# aasrc_AASRC_CFG_02D00000h register map
Vendor: Texas Instruments
Peripheral module from a debugger description file (folder AM275x).
Registers are 32-bit, access per field, reset 0x0 unless marked. A register's access mark holds for its fields unless they carry their own. Offsets are as the file gives them; lines under a group give offsets from that group; [hi:lo] are bit positions; {n}, {i} and the like mark numbered series; 'fields as' and 'values as' point back to an identical list; <NAME> marks a mode.

## aasrc_cfg (part 1 of 2)
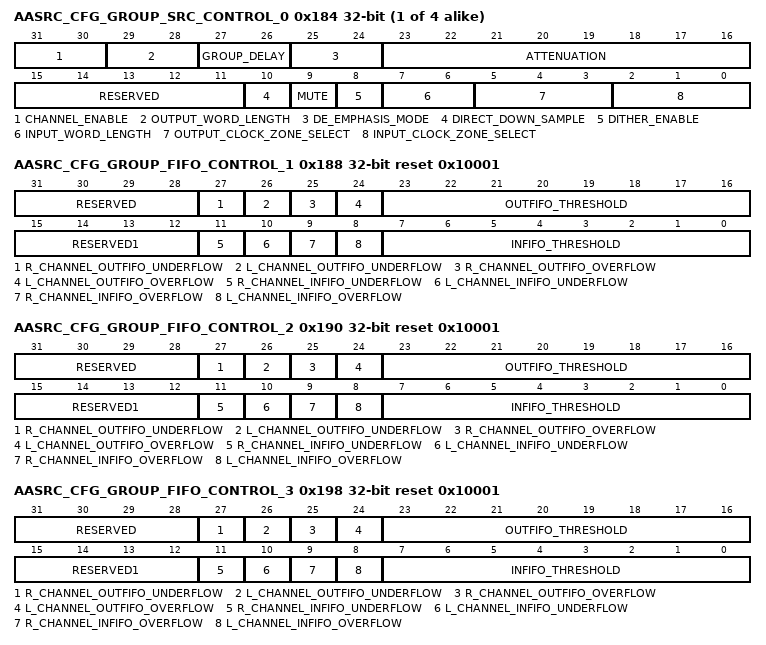
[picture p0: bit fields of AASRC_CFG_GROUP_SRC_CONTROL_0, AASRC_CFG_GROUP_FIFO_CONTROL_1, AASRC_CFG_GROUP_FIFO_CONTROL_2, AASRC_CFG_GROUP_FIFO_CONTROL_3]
{0x184+8i} AASRC_CFG_GROUP_SRC_CONTROL_{i} (i=0..3) — This is where all the SRCs of Group{i} is configured
  [31:30] CHANNEL_ENABLE rw — Setting this enables the Channels of Group{i} SRCs The output FIFOs for the stream must be enabled before the input FIFOs 00: No channel enabled 01: Only Right Channel enabled 10: Only Left Channel enabled 11: Both channels enabled Clearing this register will clear the data path
  [29:28] OUTPUT_WORD_LENGTH rw — These bits select the word length for the Group{i} SRC output data The word length reduction is performed by utilizing triangular PDF dithering 0: 24 Bits [Default] 1: 20 Bits 2: 18 Bits 3: 16 Bits
  [27:26] GROUP_DELAY rw — These bits select the interpolation filter group delay by configuring the number of samples which are pre-buffered prior to the re-sampler function 0: 64 Samples [Default] 1: 32 Samples 2: 16 Samples 3: 8 Samples
  [25:24] DE_EMPHASIS_MODE rw — These bits are utilized to enable or disable the digital de-emphasis filter manually The de-emphasis filter is intended to process 50/15s pre-emphasized audio material at the following input sampling rates 0: De-Emphasis Disabled [Default] 1: De-Emphasis Enabled for fS = 48kHz 2: De-Emphasis Enabled for fS = 441kHz 3: De-Emphasis Enabled for fS = 32kHz
  [23:16] ATTENUATION rw — These bits are utilized to configure the Group{i} SRC digital output attenuation for the stream Output Attenuation [dB] = N 05, where N = Attenuation[7:0]DEC
  [15:11] RESERVED ro — Always read as 0
  [10] DIRECT_DOWN_SAMPLE rw — This bit selects the mode of the decimation function, either true decimation filter or direct down-sampling without filtering DDN Decimation Function. Note: Direct down-sampling should only be used when the output sampling rate is higher than the input sampling rate When the output sampling rate is equal to or lower than the input sampling rate, the Decimation Filter must be used in order to avoid aliasing 0 Decimation Filter1 Direct Down Sampling
  [9] MUTE rw — This bit enables or disables the Group{i} SRC output soft mute function; output data set to all zeros 0 Mute disabled1 Mute enabled
  [8] DITHER_ENABLE rw — This bit enables or disables the Group{i} SRC filters dithering 0 Dithering disabled1 Dithering enabled
  [7:6] INPUT_WORD_LENGTH rw — These bits select the word length for the SRC0 input data 0: 24 Bits [Default] 1: 20 Bits 2: 18 Bits 3: 16 Bits
  [5:3] OUTPUT_CLOCK_ZONE_SELECT rw — This selects the output clock zone for the Group{i} SRCs It can select between the 4 external audio clock zones Based on this number rate and stamp is passed to the Stream0 Sample rate converter from respective clock recovery loop 00: This selects the Clock Recovery loop 0 01: This selects the Clock Recovery loop 1 10: This selects the Clock Recovery loop 2 11: This selects the Clock Recovery loop 3 In case of Galileo other values are not valid
  [2:0] INPUT_CLOCK_ZONE_SELECT rw — This selects the input clock zone for the Group{i} SRCs It can select between the 4 external audio clock zones Based on this number rate and stamp is passed to the Stream0 Sample rate converter from respective clock recovery loop 000: This selects the Clock Recovery loop 0 001: This selects the Clock Recovery loop 1 010: This selects the Clock Recovery loop 2 011: This selects the Clock Recovery loop 3 In case of Galileo other values are not valid
0x188 AASRC_CFG_GROUP_FIFO_CONTROL_1 reset 0x10001 — This register configures the FIFO settings for Group 1.
  [31:28] RESERVED ro — Always read as 0
  [27] R_CHANNEL_OUTFIFO_UNDERFLOW ro — This signal is set to 1 when any of the Right Channel OUTFIFO for Group1 SRCs is underflowed 0 No underflow is detected1 Underflow is detected
  [26] L_CHANNEL_OUTFIFO_UNDERFLOW ro — This signal is set to 1 when any of the Left Channel OUTFIFO for Group1 SRCs is underflowed 0 No underflow is detected1 Underflow is detected
  [25] R_CHANNEL_OUTFIFO_OVERFLOW ro — This signal is set to 1 when any of the Right Channel OUTFIFO for Group1 SRCs is overflowed 0 No overflow is detected1 Overflow is detected
  [24] L_CHANNEL_OUTFIFO_OVERFLOW ro — This signal is set to 1 when any of the Left Channel OUTFIFO for Group1 SRCs is overflowed 0 No overflow is detected1 Overflow is detected
  [23:16] OUTFIFO_THRESHOLD rw — This is the number of samples that must be available for the interrupt and Group1 SRCs OUTFIFOs event to fire
  [15:12] RESERVED1 ro — Always read as 0
  [11] R_CHANNEL_INFIFO_UNDERFLOW ro — This signal is set to 1 when any of the Right Channel INFIFO for Group1 SRCs is underflowed 0 No underflow is detected1 Underflow is detected
  [10] L_CHANNEL_INFIFO_UNDERFLOW ro — This signal is set to 1 when any of the Left Channel INFIFO for Group1 SRCs is underflowed 0 No underflow is detected1 Underflow is detected
  [9] R_CHANNEL_INFIFO_OVERFLOW ro — This signal is set to 1 when any of the Right Channel INFIFO for Group1 SRCs is overflowed 0 No overflow is detected1 Overflow is detected
  [8] L_CHANNEL_INFIFO_OVERFLOW ro — This signal is set to 1 when any of the Left Channel INFIFO for Group1 SRCs is overflowed 0 No overflow is detected1 Overflow is detected
  [7:0] INFIFO_THRESHOLD rw — This is the number of samples that must be available for the interrupt and Group1 SRCs INFIFOs event to fire
0x190 AASRC_CFG_GROUP_FIFO_CONTROL_2 reset 0x10001 — This register configures the FIFO settings for Group 2
  [31:28] RESERVED ro — Always read as 0
  [27] R_CHANNEL_OUTFIFO_UNDERFLOW ro — This signal is set to 1 when any of the Right Channel OUTFIFO for Group2 SRCs is underflowed 0 No underflow is detected1 Underflow is detected
  [26] L_CHANNEL_OUTFIFO_UNDERFLOW ro — This signal is set to 1 when any of the Left Channel OUTFIFO for Group2 SRCs is underflowed 0 No underflow is detected1 Underflow is detected
  [25] R_CHANNEL_OUTFIFO_OVERFLOW ro — This signal is set to 1 when any of the Right Channel OUTFIFO for Group2 SRCs is overflowed 0 No overflow is detected1 Overflow is detected
  [24] L_CHANNEL_OUTFIFO_OVERFLOW ro — This signal is set to 1 when any of the Left Channel OUTFIFO for Group2 SRCs is overflowed 0 No overflow is detected1 Overflow is detected
  [23:16] OUTFIFO_THRESHOLD rw — This is the number of samples that must be available for the interrupt and Group2 SRCs OUTFIFOs event to fire
  [15:12] RESERVED1 ro — Always read as 0
  [11] R_CHANNEL_INFIFO_UNDERFLOW ro — This signal is set to 1 when any of the Right Channel INFIFO for Group2 SRCs is underflowed 0 No underflow is detected1 Underflow is detected
  [10] L_CHANNEL_INFIFO_UNDERFLOW ro — This signal is set to 1 when any of the Left Channel INFIFO for Group2 SRCs is underflowed 0 No underflow is detected1 Underflow is detected
  [9] R_CHANNEL_INFIFO_OVERFLOW ro — This signal is set to 1 when any of the Right Channel INFIFO for Group2 SRCs is overflowed 0 No overflow is detected1 Overflow is detected
  [8] L_CHANNEL_INFIFO_OVERFLOW ro — This signal is set to 1 when any of the Left Channel INFIFO for Group2 SRCs is overflowed 0 No overflow is detected1 Overflow is detected
  [7:0] INFIFO_THRESHOLD rw — This is the number of samples that must be available for the interrupt and Group2 SRCs INFIFOs event to fire
0x198 AASRC_CFG_GROUP_FIFO_CONTROL_3 reset 0x10001 — This register configures the FIFO settings for Group 3
  [31:28] RESERVED ro — Always read as 0
  [27] R_CHANNEL_OUTFIFO_UNDERFLOW ro — This signal is set to 1 when any of the Right Channel OUTFIFO for Group3 SRCs is underflowed 0 No underflow is detected1 Underflow is detected
  [26] L_CHANNEL_OUTFIFO_UNDERFLOW ro — This signal is set to 1 when any of the Left Channel OUTFIFO for Group3 SRCs is underflowed 0 No underflow is detected1 Underflow is detected
  [25] R_CHANNEL_OUTFIFO_OVERFLOW ro — This signal is set to 1 when any of the Right Channel OUTFIFO for Group3 SRCs is overflowed 0 No overflow is detected1 Overflow is detected
  [24] L_CHANNEL_OUTFIFO_OVERFLOW ro — This signal is set to 1 when any of the Left Channel OUTFIFO for Group3 SRCs is overflowed 0 No overflow is detected1 Overflow is detected
  [23:16] OUTFIFO_THRESHOLD rw — This is the number of samples that must be available for the interrupt and Group3 SRCs OUTFIFOs event to fire
  [15:12] RESERVED1 ro — Always read as 0
  [11] R_CHANNEL_INFIFO_UNDERFLOW ro — This signal is set to 1 when any of the Right Channel INFIFO for Group3 SRCs is underflowed 0 No underflow is detected1 Underflow is detected
  [10] L_CHANNEL_INFIFO_UNDERFLOW ro — This signal is set to 1 when any of the Left Channel INFIFO for Group3 SRCs is underflowed 0 No underflow is detected1 Underflow is detected
  [9] R_CHANNEL_INFIFO_OVERFLOW ro — This signal is set to 1 when any of the Right Channel INFIFO for Group3 SRCs is overflowed 0 No overflow is detected1 Overflow is detected
  [8] L_CHANNEL_INFIFO_OVERFLOW ro — This signal is set to 1 when any of the Left Channel INFIFO for Group3 SRCs is overflowed 0 No overflow is detected1 Overflow is detected
  [7:0] INFIFO_THRESHOLD rw — This is the number of samples that must be available for the interrupt and Group3 SRCs INFIFOs event to fire
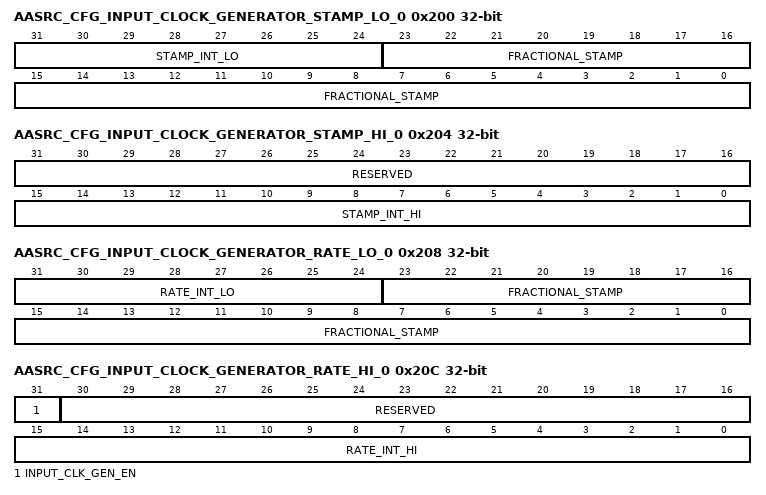
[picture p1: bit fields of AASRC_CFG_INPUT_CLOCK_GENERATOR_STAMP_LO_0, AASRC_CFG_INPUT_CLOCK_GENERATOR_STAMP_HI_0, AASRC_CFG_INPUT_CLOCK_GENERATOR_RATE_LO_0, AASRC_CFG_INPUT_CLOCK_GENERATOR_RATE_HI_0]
0x200 AASRC_CFG_INPUT_CLOCK_GENERATOR_STAMP_LO_0 rw — This is the value of the next timestamp for the input clock generator 0. This contains the 24 bit fractional and the first 8 bits of the integer. This register is used to generate soft clock
  [31:24] STAMP_INT_LO — This is the lower 8 bits of the integer multiple of the next timestamp for the clock source This register will be updated by adding the Clock Generator Rate to the Stamp value whenever the Free Running Counter passes the Stamp value
  [23:0] FRACTIONAL_STAMP — This is the fractional portion of the next timestamp for the clock source This register will be updated by adding the Clock Generator Rate to the Stamp value whenever the Free Running Counter passes the Stamp value
0x204 AASRC_CFG_INPUT_CLOCK_GENERATOR_STAMP_HI_0 — This is the value of the rate for the clock generator 0. This contains the 24 bit fractional and the first 8 bits of the integer. This is based on a free running counter running on sys_clk. This register is used to generate soft clock.
  [31:16] RESERVED ro — Always read as 0
  [15:0] STAMP_INT_HI rw — This is the upper 16 bits of the integer multiple of the next timestamp for the clock source This register will be updated by adding the Clock Generator Rate to the Stamp value whenever the Free Running Counter passes the Stamp value
0x208 AASRC_CFG_INPUT_CLOCK_GENERATOR_RATE_LO_0 rw — This is the value of the rate for the clock generator 0. This contains the 24 bit fractional and the first 8 bits of the integer. This is based on a free running counter running on sys_clk. This register is used to generate soft clock.
  [31:24] RATE_INT_LO — This is the lower 8 bits of the integer multiple of the rate for the clock source This register will be added with the Clock Generator Stamp to update the Stamp value whenever the Free Running Counter passes the Stamp value
  [23:0] FRACTIONAL_STAMP — This is the fractional portion of the rate for the clock source
0x20C AASRC_CFG_INPUT_CLOCK_GENERATOR_RATE_HI_0 — This is the value of the rate for the clock generator 0. This contains the upper 16 bits of the integer and the enable for the clock generator. This register is used to generate soft clock.
  [31] INPUT_CLK_GEN_EN rw — This signal enables the Input Clock Generator 0 0 Clock generator disabled1 Clock generator enabled
  [30:16] RESERVED ro — Always read as 0
  [15:0] RATE_INT_HI rw — This is the lower 8 bits of the integer multiple of the rate for the clock source This register will be added with the Clock Generator Stamp to update the Stamp value whenever the Free Running Counter passes the Stamp value
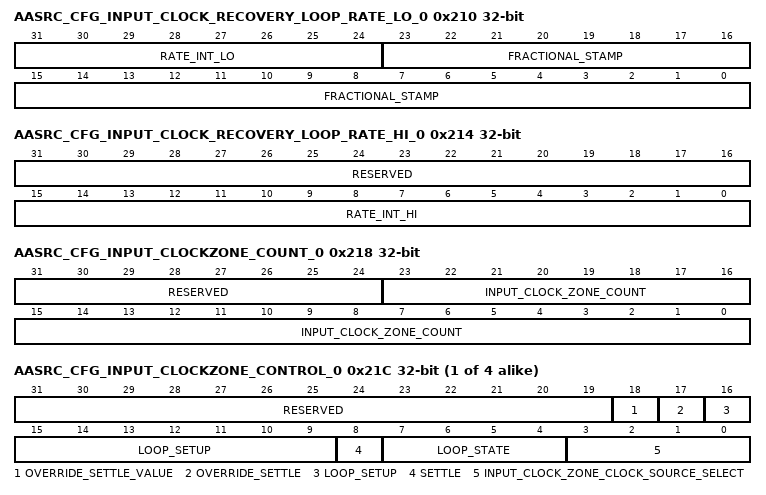
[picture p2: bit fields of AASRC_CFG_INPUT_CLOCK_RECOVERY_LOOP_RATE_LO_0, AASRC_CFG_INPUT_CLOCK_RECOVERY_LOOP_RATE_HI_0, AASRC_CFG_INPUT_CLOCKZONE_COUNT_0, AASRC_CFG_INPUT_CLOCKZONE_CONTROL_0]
0x210 AASRC_CFG_INPUT_CLOCK_RECOVERY_LOOP_RATE_LO_0 ro — This is the value of the rate for the input clock recovery loop 0. This contains the 24 bit fractional and the first 8 bits of the integer
  [31:24] RATE_INT_LO — This is the lower 8 bits of the integer multiple of the rate for the intput clock recovery loop 0
  [23:0] FRACTIONAL_STAMP — This is the fractional portion of the rate for the intput clock recovery loop 0
0x214 AASRC_CFG_INPUT_CLOCK_RECOVERY_LOOP_RATE_HI_0 ro — This is the value of the rate for the input clock recovery loop 0. This contains the upper 16 bits of the rate input clock recovery loop
  [31:16] RESERVED — Always read as 0
  [15:0] RATE_INT_HI — This is the upper 16 bits of the integer multiple of the rate for the intput clock recovery loop 0
0x218 AASRC_CFG_INPUT_CLOCKZONE_COUNT_0 ro — Free Running counter for clockzone 0
  [31:24] RESERVED — Always read as 0
  [23:0] INPUT_CLOCK_ZONE_COUNT — This gives the value of free running counter at every posedge of sync signal
{0x21C+0x80*i} AASRC_CFG_INPUT_CLOCKZONE_CONTROL_{i} (i=0..3) — This is the configuration for Input Clock zone {i}
  [31:19] RESERVED ro — Always read as 0
  [18] OVERRIDE_SETTLE_VALUE rw — Value written to this field will be used as settle if override settle signal is set
  [17] OVERRIDE_SETTLE rw — This signal override the settle of input clock zone {i} clock recovery loop 0 Settle from clock recovery will be used1 Value written to override settle value will be used
  [16:9] LOOP_SETUP rw — This is the setting for input clock recovery loop for zone {i} 8h00: Slow loop 8h40: Medium1 loop 8h80: Medium2 loop 8hC0: Slow loop
  [8] SETTLE ro — This signals sets to 1 when clock recovery loop is settled
  [7:4] LOOP_STATE ro — Loop debug State
  [3:0] INPUT_CLOCK_ZONE_CLOCK_SOURCE_SELECT rw — This selects the 8x1 and 2x1 mux structure for input clock zone {i} 1xxx: Clock comes from output clock gen 0 0000-0111: Selects rxsync signal from 0-7
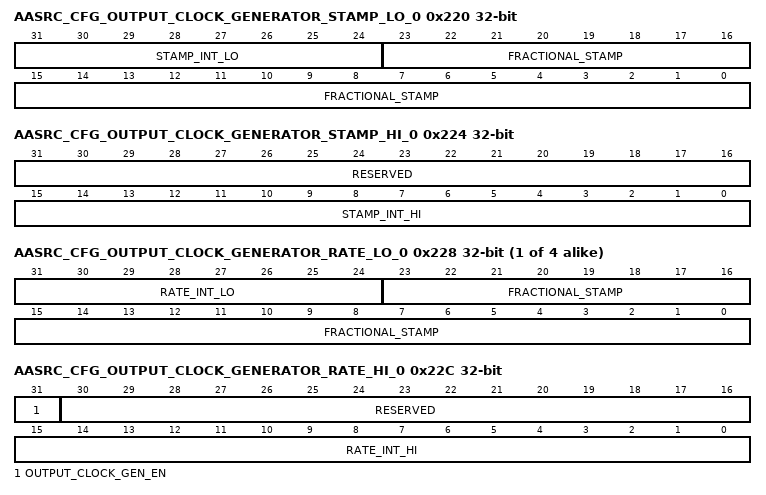
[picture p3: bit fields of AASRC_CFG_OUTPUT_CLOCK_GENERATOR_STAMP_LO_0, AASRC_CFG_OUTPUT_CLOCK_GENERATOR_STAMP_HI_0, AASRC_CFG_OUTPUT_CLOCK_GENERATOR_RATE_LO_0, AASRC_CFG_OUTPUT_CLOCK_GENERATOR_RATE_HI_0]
0x220 AASRC_CFG_OUTPUT_CLOCK_GENERATOR_STAMP_LO_0 rw — This is the value of the next timestamp for the Output clock generator 0. This contains the 24 bit fractional and the first 8 bits of the integer. This register is used to generate soft clock
  fields as AASRC_CFG_INPUT_CLOCK_GENERATOR_STAMP_LO_0
0x224 AASRC_CFG_OUTPUT_CLOCK_GENERATOR_STAMP_HI_0 — This is the value of the next timestamp for the Output clock generator 0. This contains the first 16 bits of the integer. This register is used to generate soft clock.
  fields as AASRC_CFG_INPUT_CLOCK_GENERATOR_STAMP_HI_0
{0x228+0x80*i} AASRC_CFG_OUTPUT_CLOCK_GENERATOR_RATE_LO_{i} rw (i=0..3) — This is the value of the rate for the clock generator {i}. This contains the 24 bit fractional and the first 8 bits of the integer. This is based on a free running counter running on sys_clk. This register is used to generate soft clock
  fields as AASRC_CFG_INPUT_CLOCK_GENERATOR_RATE_LO_0
0x22C AASRC_CFG_OUTPUT_CLOCK_GENERATOR_RATE_HI_0 — This is the value of the rate for the clock generator 0. This contains the upper 16 bits of the integer and the enable for the clock generator. This register is used to generate soft clock.
  [31] OUTPUT_CLOCK_GEN_EN rw — This signal enables the Output Clock Generator 0
  [30:16] RESERVED ro — Always read as 0
  [15:0] RATE_INT_HI rw — This is the lower 8 bits of the integer multiple of the rate for the clock source This register will be added with the Clock Generator Stamp to update the Stamp value whenever the Free Running Counter passes the Stamp value
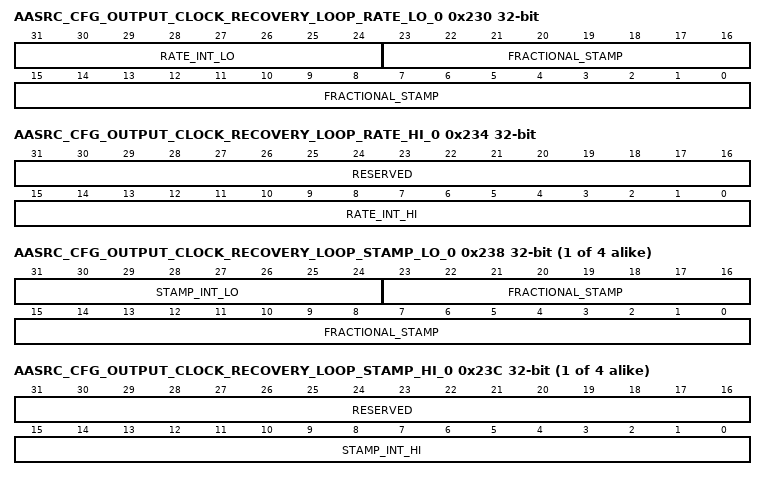
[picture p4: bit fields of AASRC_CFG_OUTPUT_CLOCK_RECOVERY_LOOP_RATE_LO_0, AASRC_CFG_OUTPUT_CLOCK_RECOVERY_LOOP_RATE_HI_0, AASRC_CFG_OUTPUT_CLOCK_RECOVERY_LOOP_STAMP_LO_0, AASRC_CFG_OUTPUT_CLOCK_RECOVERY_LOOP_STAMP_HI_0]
0x230 AASRC_CFG_OUTPUT_CLOCK_RECOVERY_LOOP_RATE_LO_0 ro — This is the value of the rate for the Output clock recovery loop 0. This contains the 24 bit fractional and the first 8 bits of the integer.
  [31:24] RATE_INT_LO — This is the lower 8 bits of the integer multiple of the rate for the outtput clock recovery loop 0
  [23:0] FRACTIONAL_STAMP — This is the fractional portion of the rate for the outtput clock recovery loop 0
0x234 AASRC_CFG_OUTPUT_CLOCK_RECOVERY_LOOP_RATE_HI_0 ro — This is the value of the rate for the Output clock recovery loop 0. This contains the upper 16 bits of the Output clock recovery loop
  [31:16] RESERVED — Always read as 0
  [15:0] RATE_INT_HI — This is the Upper 16 bits of the integer multiple of the rate for the outtput clock recovery loop 0
{0x238+0x80*i} AASRC_CFG_OUTPUT_CLOCK_RECOVERY_LOOP_STAMP_LO_{i} ro (i=0..3) — This is the value of the timestamp for the Output clock recovery loop {i}. This contains the 24 bit fractional and the first 8 bits of the integer
  [31:24] STAMP_INT_LO — This is the lower 8 bits of the integer multiple of the next timestamp for the clock source This register will be updated when output fifo event occurs
  [23:0] FRACTIONAL_STAMP — This is the fractional portion of the next timestamp for the clock source This register will be updated when output fifo event occurs
{0x23C+0x80*i} AASRC_CFG_OUTPUT_CLOCK_RECOVERY_LOOP_STAMP_HI_{i} ro (i=0..3) — This is the value of the next timestamp for the Output clock recovery loop {i}. This contains the first 16 bits of the integer
  [31:16] RESERVED — Always read as 0
  [15:0] STAMP_INT_HI — This is the upper 16 bits of the integer multiple of the next timestamp for the clock recovery loop This register will be updated when output fifo event occurs
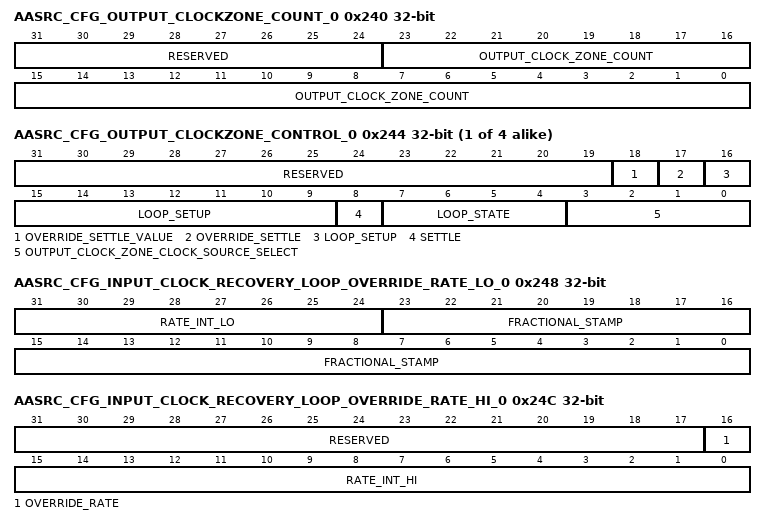
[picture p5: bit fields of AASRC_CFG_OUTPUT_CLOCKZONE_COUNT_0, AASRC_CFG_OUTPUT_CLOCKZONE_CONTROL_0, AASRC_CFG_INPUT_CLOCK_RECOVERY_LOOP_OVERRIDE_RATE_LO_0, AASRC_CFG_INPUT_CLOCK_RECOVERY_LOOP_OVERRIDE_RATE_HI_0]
0x240 AASRC_CFG_OUTPUT_CLOCKZONE_COUNT_0 ro — Free Running counter for clockzone 0
  [31:24] RESERVED — Always read as 0
  [23:0] OUTPUT_CLOCK_ZONE_COUNT — This gives the value of free running counter at every posedge of sync signal
{0x244+0x80*i} AASRC_CFG_OUTPUT_CLOCKZONE_CONTROL_{i} (i=0..3) — This is the configuration for Output Clock zone {i}
  [31:19] RESERVED ro — Always read as 0
  [18] OVERRIDE_SETTLE_VALUE rw — Value written to this field will be used as settle if override settle signal is set
  [17] OVERRIDE_SETTLE rw — This signal override the settle of output clock zone {i} clock recovery loop 0 Settle from clock recovery will be used1 Value written to override settle value will be used
  [16:9] LOOP_SETUP rw — This is the setting for input clock recovery loop for zone {i} 8h00: Slow loop 8h40: Medium1 loop 8h80: Medium2 loop 8hC0: Slow loop
  [8] SETTLE ro — This signals sets to 1 when clock recovery loop is settled
  [7:4] LOOP_STATE ro — Loop debug state
  [3:0] OUTPUT_CLOCK_ZONE_CLOCK_SOURCE_SELECT rw — This selects the 8x1 and 2x1 mux structure for output clock zone {i} 1xxx: Clock comes from output clock gen 0 0000-0111: Selects txsync signal from 0-7
0x248 AASRC_CFG_INPUT_CLOCK_RECOVERY_LOOP_OVERRIDE_RATE_LO_0 rw — This is the override value of the rate for the input clock recovery loop 0. This contains the 24 bit fractional and the first 8 bits of the integer
  [31:24] RATE_INT_LO — This is the lower 8 bits of the integer multiple of the rate for the override clock recovery loop 0
  [23:0] FRACTIONAL_STAMP — This is the fractional portion of the rate for the override clock recovery loop 0
0x24C AASRC_CFG_INPUT_CLOCK_RECOVERY_LOOP_OVERRIDE_RATE_HI_0 — This is the Override value of the rate for the input clock recovery loop 0. This contains the upper 16 bits of the rate input clock recovery loop
  [31:17] RESERVED ro — Always read as 0
  [16] OVERRIDE_RATE rw — This is the upper 16 bits of the integer multiple of the rate for the override clock recovery loop 0
  [15:0] RATE_INT_HI rw — This is the upper 16 bits of the integer multiple of the rate for the override clock recovery loop 0
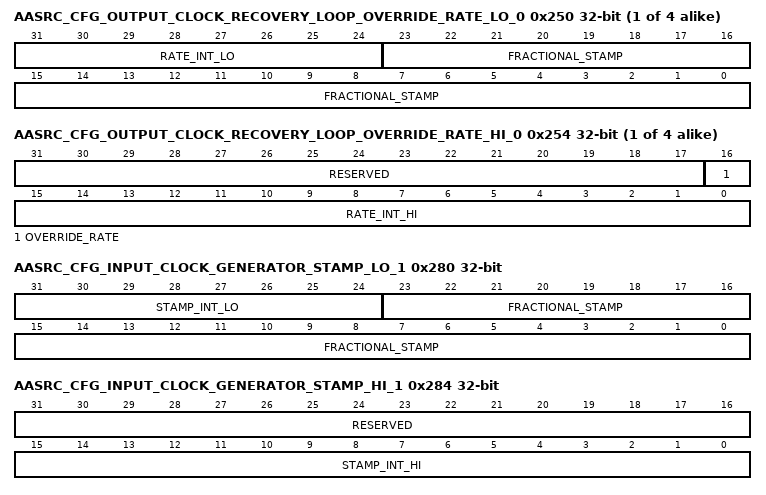
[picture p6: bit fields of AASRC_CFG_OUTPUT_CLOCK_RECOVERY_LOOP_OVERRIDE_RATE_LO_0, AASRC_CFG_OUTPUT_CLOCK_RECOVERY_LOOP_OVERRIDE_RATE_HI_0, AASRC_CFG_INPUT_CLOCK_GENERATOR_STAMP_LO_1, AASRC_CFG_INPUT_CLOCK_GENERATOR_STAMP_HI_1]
{0x250+0x80*i} AASRC_CFG_OUTPUT_CLOCK_RECOVERY_LOOP_OVERRIDE_RATE_LO_{i} rw (i=0..3) — This is the override value of the rate for the Output clock recovery loop {i}. This contains the 24 bit fractional and the first 8 bits of the integer
  [31:24] RATE_INT_LO — This is the lower 8 bits of the integer multiple of the rate for the output override clock recovery loop {i}
  [23:0] FRACTIONAL_STAMP — This is the fractional portion of the rate for the output override clock recovery loop {i}
{0x254+0x80*i} AASRC_CFG_OUTPUT_CLOCK_RECOVERY_LOOP_OVERRIDE_RATE_HI_{i} (i=0..3) — This is the override value of the rate for the Output clock recovery loop {i}. This contains the upper 16 bits of the Output clock recovery loop
  [31:17] RESERVED ro — Always read as 0
  [16] OVERRIDE_RATE rw — This is the upper 16 bits of the integer multiple of the rate for the output override clock recovery loop {i}
  [15:0] RATE_INT_HI rw — This is the Upper 16 bits of the integer multiple of the rate for the output override clock recovery loop {i}
0x280 AASRC_CFG_INPUT_CLOCK_GENERATOR_STAMP_LO_1 rw — This is the value of the next timestamp for the input clock generator 1. This contains the 24 bit fractional and the first 8 bits of the integer. This register is used to generate soft clock.
  fields as AASRC_CFG_INPUT_CLOCK_GENERATOR_STAMP_LO_0
0x284 AASRC_CFG_INPUT_CLOCK_GENERATOR_STAMP_HI_1 — This is the value of the next timestamp for the input clock generator 1. This contains the first 16 bits of the integer. This register is used to generate soft clock.
  fields as AASRC_CFG_INPUT_CLOCK_GENERATOR_STAMP_HI_0
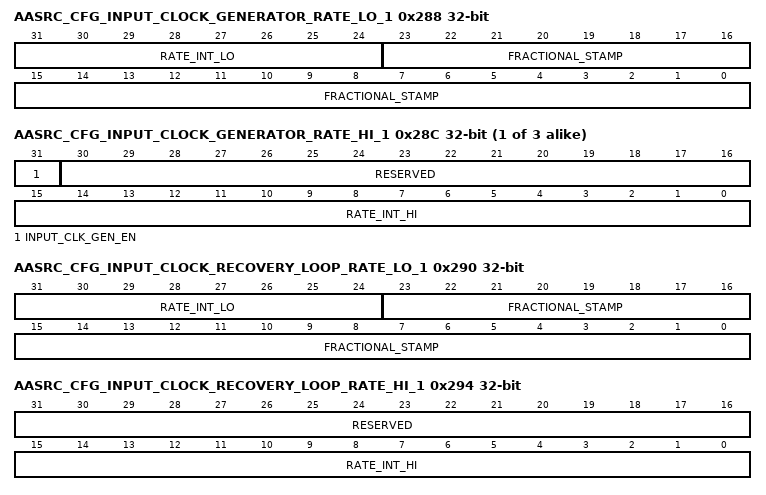
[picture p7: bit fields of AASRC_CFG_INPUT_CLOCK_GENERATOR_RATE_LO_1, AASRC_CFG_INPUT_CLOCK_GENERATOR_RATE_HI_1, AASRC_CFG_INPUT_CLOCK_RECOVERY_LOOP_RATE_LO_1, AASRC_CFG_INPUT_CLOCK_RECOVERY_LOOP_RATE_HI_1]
0x288 AASRC_CFG_INPUT_CLOCK_GENERATOR_RATE_LO_1 rw — This is the value of the rate for the clock generator 1. This contains the 24 bit fractional and the first 8 bits of the integer. This is based on a free running counter running on sys_clk. This register is used to generate soft clock.
  fields as AASRC_CFG_INPUT_CLOCK_GENERATOR_RATE_LO_0
{0x20C+0x80*i} AASRC_CFG_INPUT_CLOCK_GENERATOR_RATE_HI_{i} (i=1..3) — This is the value of the rate for the clock generator {i}. This contains the upper 16 bits of the integer and the enable for the clock generator. This register is used to generate soft clock
  [31] INPUT_CLK_GEN_EN rw — This signal enables the Input Clock Generator {i} 0 Clock generator disabled1 Clock generator enabled
  [30:16] RESERVED ro — Always read as 0
  [15:0] RATE_INT_HI rw — This is the lower 8 bits of the integer multiple of the rate for the clock source This register will be added with the Clock Generator Stamp to update the Stamp value whenever the Free Running Counter passes the Stamp value
0x290 AASRC_CFG_INPUT_CLOCK_RECOVERY_LOOP_RATE_LO_1 ro — This is the value of the rate for the input clock recovery loop 1. This contains the 24 bit fractional and the first 8 bits of the integer
  [31:24] RATE_INT_LO — This is the lower 8 bits of the integer multiple of the rate for the intput clock recovery loop 1
  [23:0] FRACTIONAL_STAMP — This is the fractional portion of the rate for the intput clock recovery loop 1
0x294 AASRC_CFG_INPUT_CLOCK_RECOVERY_LOOP_RATE_HI_1 ro — This is the value of the rate for the input clock recovery loop 1. This contains the upper 16 bits of the rate input clock recovery loop
  [31:16] RESERVED — Always read as 0
  [15:0] RATE_INT_HI — This is the upper 16 bits of the integer multiple of the rate for the intput clock recovery loop 1
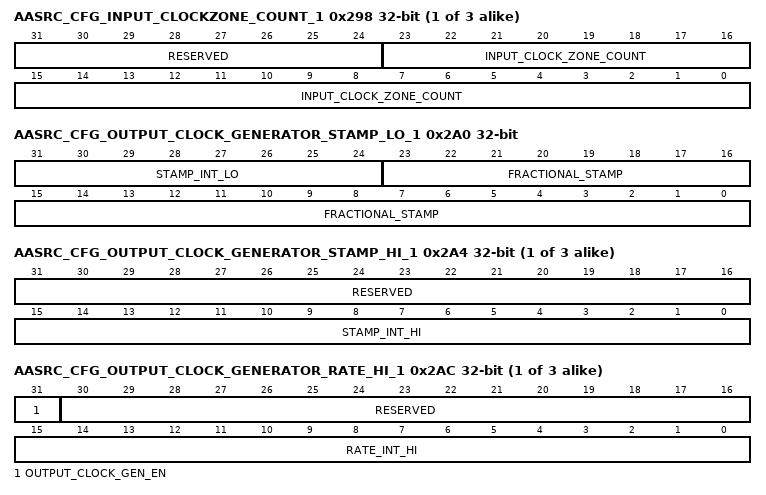
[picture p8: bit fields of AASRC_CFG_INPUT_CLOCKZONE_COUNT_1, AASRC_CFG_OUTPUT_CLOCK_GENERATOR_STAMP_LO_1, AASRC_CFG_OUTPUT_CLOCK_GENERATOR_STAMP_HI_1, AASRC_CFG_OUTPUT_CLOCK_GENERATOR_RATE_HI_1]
{0x218+0x80*i} AASRC_CFG_INPUT_CLOCKZONE_COUNT_{i} ro (i=1..3) — Free Running counter for clock zone {i}
  fields as AASRC_CFG_INPUT_CLOCKZONE_COUNT_0
0x2A0 AASRC_CFG_OUTPUT_CLOCK_GENERATOR_STAMP_LO_1 rw — This is the value of the next timestamp for the Output clock generator a. This contains the 24 bit fractional and the first 8 bits of the integer. This register is used to generate soft clock
  fields as AASRC_CFG_INPUT_CLOCK_GENERATOR_STAMP_LO_0
{0x224+0x80*i} AASRC_CFG_OUTPUT_CLOCK_GENERATOR_STAMP_HI_{i} (i=1..3) — This is the value of the next timestamp for the Output clock generator {i}. This contains the first 16 bits of the integer. This register is used to generate soft clock
  fields as AASRC_CFG_INPUT_CLOCK_GENERATOR_STAMP_HI_0
{0x22C+0x80*i} AASRC_CFG_OUTPUT_CLOCK_GENERATOR_RATE_HI_{i} (i=1..3) — This is the value of the rate for the clock generator {i}. This contains the upper 16 bits of the integer and the enable for the clock generator. This register is used to generate soft clock
  [31] OUTPUT_CLOCK_GEN_EN rw — This signal enables the Output Clock Generator {i} 0 Clock generator disabled1 Clock generator enabled
  [30:16] RESERVED ro — Always read as 0
  [15:0] RATE_INT_HI rw — This is the lower 8 bits of the integer multiple of the rate for the clock source This register will be added with the Clock Generator Stamp to update the Stamp value whenever the Free Running Counter passes the Stamp value
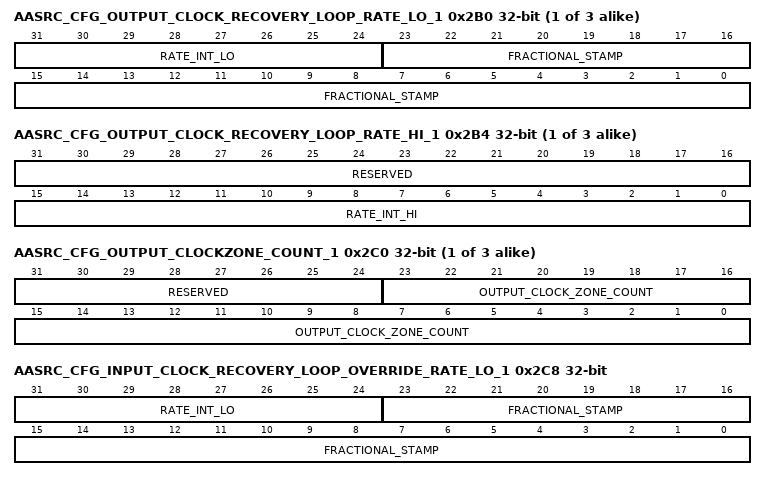
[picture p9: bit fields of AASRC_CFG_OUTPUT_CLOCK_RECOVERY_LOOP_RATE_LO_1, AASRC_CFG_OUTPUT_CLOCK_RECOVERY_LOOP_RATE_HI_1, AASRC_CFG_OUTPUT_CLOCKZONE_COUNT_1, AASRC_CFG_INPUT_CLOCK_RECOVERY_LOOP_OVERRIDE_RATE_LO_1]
{0x230+0x80*i} AASRC_CFG_OUTPUT_CLOCK_RECOVERY_LOOP_RATE_LO_{i} ro (i=1..3) — This is the value of the rate for the Output clock recovery loop {i}. This contains the 24 bit fractional and the first 8 bits of the integer
  [31:24] RATE_INT_LO — This is the lower 8 bits of the integer multiple of the rate for the output clock recovery loop {i}
  [23:0] FRACTIONAL_STAMP — This is the fractional portion of the rate for the output clock recovery loop {i}
{0x234+0x80*i} AASRC_CFG_OUTPUT_CLOCK_RECOVERY_LOOP_RATE_HI_{i} ro (i=1..3) — This is the value of the rate for the Output clock recovery loop {i}. This contains the upper 16 bits of the Output clock recovery loop
  [31:16] RESERVED — Always read as 0
  [15:0] RATE_INT_HI — This is the Upper 16 bits of the integer multiple of the rate for the output clock recovery loop {i}
{0x240+0x80*i} AASRC_CFG_OUTPUT_CLOCKZONE_COUNT_{i} ro (i=1..3) — Free Running counter for clock zone {i}
  fields as AASRC_CFG_OUTPUT_CLOCKZONE_COUNT_0
0x2C8 AASRC_CFG_INPUT_CLOCK_RECOVERY_LOOP_OVERRIDE_RATE_LO_1 rw — This is the override value of the rate for the input clock recovery loop 1. This contains the 24 bit fractional and the first 8 bits of the integer
  fields as AASRC_CFG_INPUT_CLOCK_RECOVERY_LOOP_OVERRIDE_RATE_LO_0
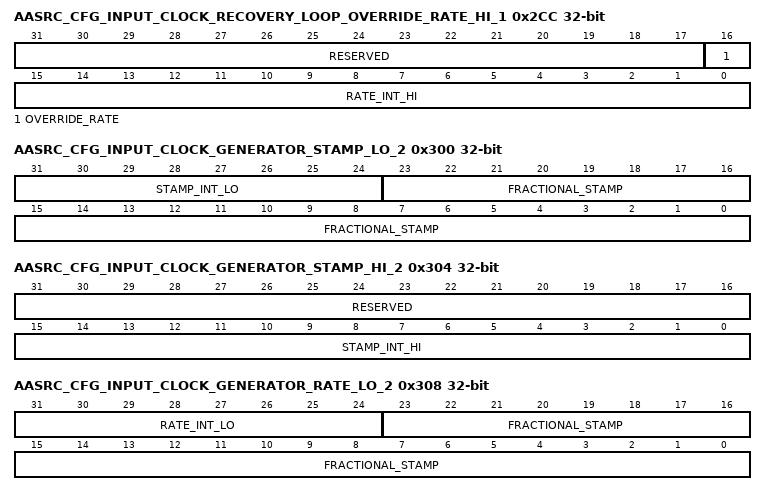
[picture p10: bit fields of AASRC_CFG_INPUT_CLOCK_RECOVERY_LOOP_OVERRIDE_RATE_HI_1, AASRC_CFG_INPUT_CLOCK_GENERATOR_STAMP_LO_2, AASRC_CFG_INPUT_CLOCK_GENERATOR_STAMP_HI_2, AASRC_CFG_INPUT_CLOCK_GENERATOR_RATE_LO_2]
0x2CC AASRC_CFG_INPUT_CLOCK_RECOVERY_LOOP_OVERRIDE_RATE_HI_1 — This is the override value of the rate for the input clock recovery loop 1. This contains the upper 16 bits of the rate input clock recovery loop
  fields as AASRC_CFG_INPUT_CLOCK_RECOVERY_LOOP_OVERRIDE_RATE_HI_0
0x300 AASRC_CFG_INPUT_CLOCK_GENERATOR_STAMP_LO_2 rw — This is the value of the next timestamp for the input clock generator 2. This contains the 24 bit fractional and the first 8 bits of the integer. This register is used to generate soft clock
  fields as AASRC_CFG_INPUT_CLOCK_GENERATOR_STAMP_LO_0
0x304 AASRC_CFG_INPUT_CLOCK_GENERATOR_STAMP_HI_2 — This is the value of the next timestamp for the input clock generator 2. This contains the first 16 bits of the integer. This register is used to generate soft clock.
  fields as AASRC_CFG_INPUT_CLOCK_GENERATOR_STAMP_HI_0
0x308 AASRC_CFG_INPUT_CLOCK_GENERATOR_RATE_LO_2 rw — This is the value of the rate for the clock generator 2. This contains the 24 bit fractional and the first 8 bits of the integer. This is based on a free running counter running on sys_clk. This register is used to generate soft clock
  fields as AASRC_CFG_INPUT_CLOCK_GENERATOR_RATE_LO_0
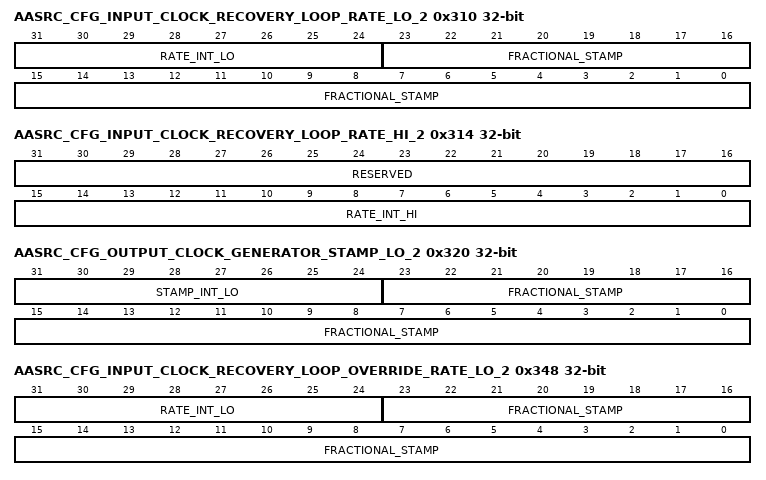
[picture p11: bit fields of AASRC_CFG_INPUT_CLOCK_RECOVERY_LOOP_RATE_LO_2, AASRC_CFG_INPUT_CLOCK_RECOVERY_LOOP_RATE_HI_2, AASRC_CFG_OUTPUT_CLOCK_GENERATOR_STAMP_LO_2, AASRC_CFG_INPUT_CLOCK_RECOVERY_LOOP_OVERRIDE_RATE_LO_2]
0x310 AASRC_CFG_INPUT_CLOCK_RECOVERY_LOOP_RATE_LO_2 ro — This is the value of the rate for the input clock recovery loop 2. This contains the 24 bit fractional and the first 8 bits of the integer.
  [31:24] RATE_INT_LO — This is the lower 8 bits of the integer multiple of the rate for the input clock recovery loop 2
  [23:0] FRACTIONAL_STAMP — This is the fractional portion of the rate for the input clock recovery loop 2
0x314 AASRC_CFG_INPUT_CLOCK_RECOVERY_LOOP_RATE_HI_2 ro — This is the value of the rate for the input clock recovery loop 2. This contains the upper 16 bits of the rate input clock recovery loop
  [31:16] RESERVED — Always read as 0
  [15:0] RATE_INT_HI — This is the upper 16 bits of the integer multiple of the rate for the input clock recovery loop 2
0x320 AASRC_CFG_OUTPUT_CLOCK_GENERATOR_STAMP_LO_2 rw — This is the value of the next timestamp for the Output clock generator a. This contains the 24 bit fractional and the first 8 bits of the integer. . This register is used to generate soft clock
  fields as AASRC_CFG_INPUT_CLOCK_GENERATOR_STAMP_LO_0
0x348 AASRC_CFG_INPUT_CLOCK_RECOVERY_LOOP_OVERRIDE_RATE_LO_2 rw — This is the override value of the rate for the input clock recovery loop 2. This contains the 24 bit fractional and the first 8 bits of the integer
  [31:24] RATE_INT_LO — This is the lower 8 bits of the integer multiple of the rate for the override clock recovery loop 2
  [23:0] FRACTIONAL_STAMP — This is the fractional portion of the rate for the override clock recovery loop 2
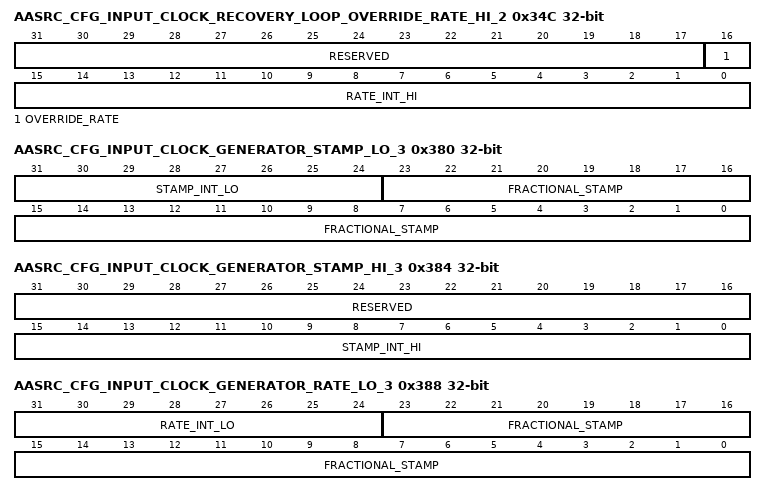
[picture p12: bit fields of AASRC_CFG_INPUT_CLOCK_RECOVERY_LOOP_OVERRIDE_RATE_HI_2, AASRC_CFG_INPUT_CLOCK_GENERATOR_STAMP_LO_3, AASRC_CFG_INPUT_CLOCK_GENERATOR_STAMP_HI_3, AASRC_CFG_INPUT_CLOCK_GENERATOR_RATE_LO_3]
0x34C AASRC_CFG_INPUT_CLOCK_RECOVERY_LOOP_OVERRIDE_RATE_HI_2 — This is the override value of the rate for the input clock recovery loop 2. This contains the upper 16 bits of the rate input clock recovery loop
  [31:17] RESERVED ro — Always read as 0
  [16] OVERRIDE_RATE rw — This is the upper 16 bits of the integer multiple of the rate for the override clock recovery loop 2
  [15:0] RATE_INT_HI rw — This is the upper 16 bits of the integer multiple of the rate for the override clock recovery loop 2
0x380 AASRC_CFG_INPUT_CLOCK_GENERATOR_STAMP_LO_3 rw — This is the value of the next timestamp for the input clock generator 3. This contains the 24 bit fractional and the first 8 bits of the integer. This register is used to generate soft clock
  fields as AASRC_CFG_INPUT_CLOCK_GENERATOR_STAMP_LO_0
0x384 AASRC_CFG_INPUT_CLOCK_GENERATOR_STAMP_HI_3 — This is the value of the next timestamp for the input clock generator 3. This contains the first 16 bits of the integer. This register is used to generate soft clock
  fields as AASRC_CFG_INPUT_CLOCK_GENERATOR_STAMP_HI_0
0x388 AASRC_CFG_INPUT_CLOCK_GENERATOR_RATE_LO_3 rw — This is the value of the rate for the clock generator 3. This contains the 24 bit fractional and the first 8 bits of the integer. This is based on a free running counter running on sys_clk. This register is used to generate soft clock
  fields as AASRC_CFG_INPUT_CLOCK_GENERATOR_RATE_LO_0
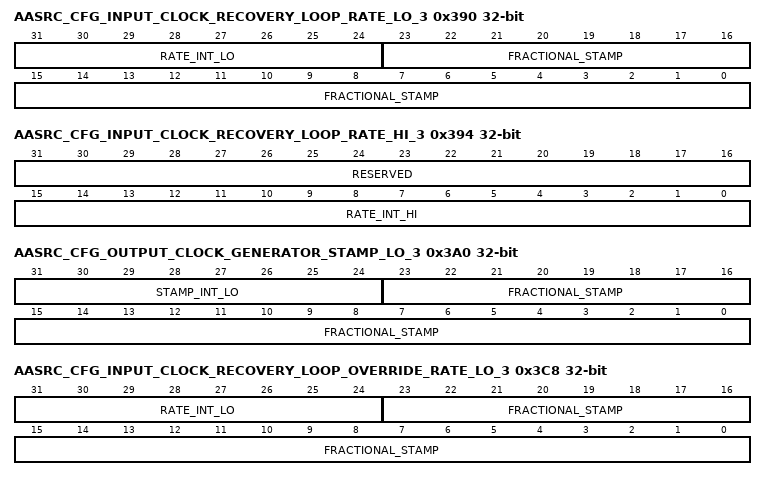
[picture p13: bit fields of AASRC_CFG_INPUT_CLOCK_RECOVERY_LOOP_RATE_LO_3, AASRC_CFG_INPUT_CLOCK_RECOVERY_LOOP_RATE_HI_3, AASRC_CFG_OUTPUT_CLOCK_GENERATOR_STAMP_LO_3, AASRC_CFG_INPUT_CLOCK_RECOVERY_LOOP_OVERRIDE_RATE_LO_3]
0x390 AASRC_CFG_INPUT_CLOCK_RECOVERY_LOOP_RATE_LO_3 ro — This is the value of the rate for the input clock recovery loop 3. This contains the 24 bit fractional and the first 8 bits of the integer
  [31:24] RATE_INT_LO — This is the lower 8 bits of the integer multiple of the rate for the input clock recovery loop 3
  [23:0] FRACTIONAL_STAMP — This is the fractional portion of the rate for the input clock recovery loop 3
0x394 AASRC_CFG_INPUT_CLOCK_RECOVERY_LOOP_RATE_HI_3 ro — This is the value of the rate for the input clock recovery loop 3. This contains the upper 16 bits of the rate input clock recovery loop
  [31:16] RESERVED — Always read as 0
  [15:0] RATE_INT_HI — This is the upper 16 bits of the integer multiple of the rate for the input clock recovery loop 3
0x3A0 AASRC_CFG_OUTPUT_CLOCK_GENERATOR_STAMP_LO_3 rw — This is the value of the next timestamp for the Output clock generator a. This contains the 24 bit fractional and the first 8 bits of the integer. . This register is used to generate soft clock
  fields as AASRC_CFG_INPUT_CLOCK_GENERATOR_STAMP_LO_0
0x3C8 AASRC_CFG_INPUT_CLOCK_RECOVERY_LOOP_OVERRIDE_RATE_LO_3 rw — This is the override value of the rate for the input clock recovery loop 3. This contains the 24 bit fractional and the first 8 bits of the integer
  [31:24] RATE_INT_LO — This is the lower 8 bits of the integer multiple of the rate for the override clock recovery loop 3
  [23:0] FRACTIONAL_STAMP — This is the fractional portion of the rate for the override clock recovery loop 3
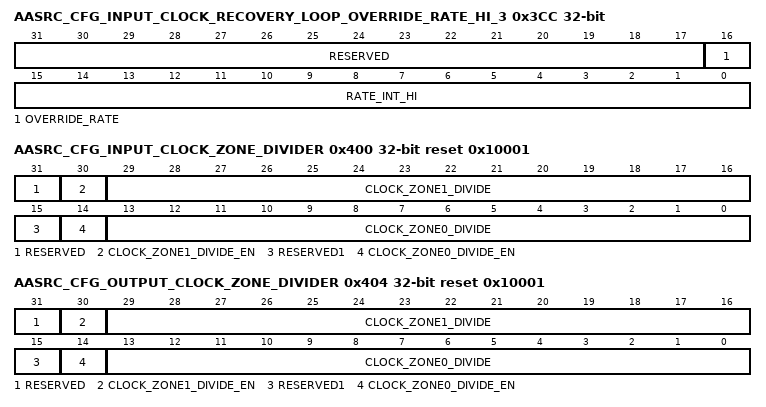
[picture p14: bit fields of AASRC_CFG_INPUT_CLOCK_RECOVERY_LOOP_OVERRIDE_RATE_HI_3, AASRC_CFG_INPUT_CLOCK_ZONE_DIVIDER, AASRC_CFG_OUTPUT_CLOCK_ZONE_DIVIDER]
0x3CC AASRC_CFG_INPUT_CLOCK_RECOVERY_LOOP_OVERRIDE_RATE_HI_3 — This is the override value of the rate for the input clock recovery loop 3. This contains the upper 16 bits of the rate input clock recovery loop
  [31:17] RESERVED ro — Always read as 0
  [16] OVERRIDE_RATE rw — This is the upper 16 bits of the integer multiple of the rate for the override clock recovery loop 3
  [15:0] RATE_INT_HI rw — This is the upper 16 bits of the integer multiple of the rate for the override clock recovery loop 3
0x400 AASRC_CFG_INPUT_CLOCK_ZONE_DIVIDER reset 0x10001 — This is the configuration for Clock divider of input zone 0 and input zone1
  [31] RESERVED ro — Always read as 0
  [30] CLOCK_ZONE1_DIVIDE_EN rw — Clock zone 1 divider enable 1'b1:Divider logic enable 1'b0:Divider logic disable 0 Clock divider disabled1 Clock divider enabled
  [29:16] CLOCK_ZONE1_DIVIDE rw — This is the setting for input clock zone1 sync signal division value
  [15] RESERVED1 ro — Always read as 0
  [14] CLOCK_ZONE0_DIVIDE_EN rw — Clock zone 0 divider enable 1'b1:Divider logic enable 1'b0:Divider logic disable 0 Clock divider disabled1 Clock divider enabled
  [13:0] CLOCK_ZONE0_DIVIDE rw — This is the setting for input clock zone0 sync signal division value
0x404 AASRC_CFG_OUTPUT_CLOCK_ZONE_DIVIDER reset 0x10001 — This is the configuration for Clock divider of output zone 0 and output zone1
  [31] RESERVED ro — Always read as 0
  [30] CLOCK_ZONE1_DIVIDE_EN rw — Clock zone 1 divider enable 1'b1:Divider logic enable 1'b0:Divider logic disable 0 Clock divider disabled1 Clock divider enabled
  [29:16] CLOCK_ZONE1_DIVIDE rw — This is the setting for output clock zone1 sync signal division value
  [15] RESERVED1 ro — Always read as 0
  [14] CLOCK_ZONE0_DIVIDE_EN rw — Clock zone 0 divider enable 1'b1:Divider logic enable 1'b0:Divider logic disable 0 Clock divider disabled1 Clock divider enabled
  [13:0] CLOCK_ZONE0_DIVIDE rw — This is the setting for output clock zone0 sync signal division value
